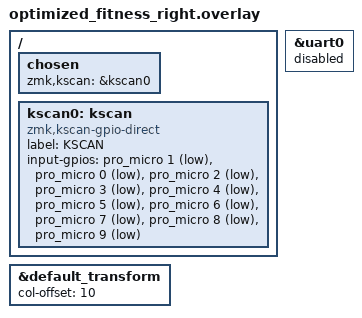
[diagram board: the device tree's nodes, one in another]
#include "optimized_fitness.dtsi"

&default_transform {
    col-offset = <10>;
};

/ {
    chosen {
        zmk,kscan = &kscan0;
    };

    kscan0: kscan {
        compatible = "zmk,kscan-gpio-direct";
        label = "KSCAN";
        input-gpios
            = <&pro_micro 1 (GPIO_ACTIVE_LOW | GPIO_PULL_UP)> // Index 11
            , <&pro_micro 0 (GPIO_ACTIVE_LOW | GPIO_PULL_UP)> // Index 12
            , <&pro_micro 2 (GPIO_ACTIVE_LOW | GPIO_PULL_UP)> // Index 13
            , <&pro_micro 3 (GPIO_ACTIVE_LOW | GPIO_PULL_UP)> // Index 14
            , <&pro_micro 4 (GPIO_ACTIVE_LOW | GPIO_PULL_UP)> // Index 15
            , <&pro_micro 5 (GPIO_ACTIVE_LOW | GPIO_PULL_UP)> // Index 16
            , <&pro_micro 6 (GPIO_ACTIVE_LOW | GPIO_PULL_UP)> // Index 17
            , <&pro_micro 7 (GPIO_ACTIVE_LOW | GPIO_PULL_UP)> // Index 18
            , <&pro_micro 8 (GPIO_ACTIVE_LOW | GPIO_PULL_UP)> // Index 19
            , <&pro_micro 9 (GPIO_ACTIVE_LOW | GPIO_PULL_UP)> // Index 20
            ;
    };
};

&uart0 {
    status = "disabled";
};
